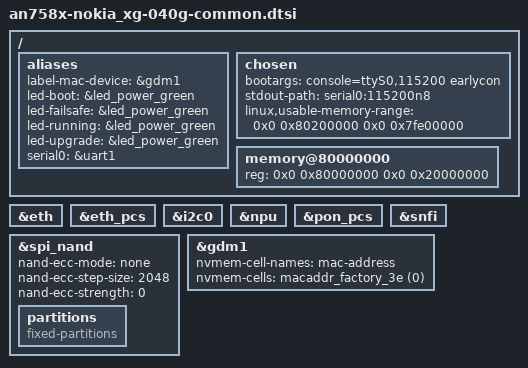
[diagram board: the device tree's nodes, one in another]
// SPDX-License-Identifier: GPL-2.0-only OR MIT

/ {
	aliases {
		label-mac-device = &gdm1;

		led-boot = &led_power_green;
		led-failsafe = &led_power_green;
		led-running = &led_power_green;
		led-upgrade = &led_power_green;

		serial0 = &uart1;
	};

	chosen {
		bootargs = "console=ttyS0,115200 earlycon";
		stdout-path = "serial0:115200n8";
		/*
		 * 这条只是上限裁剪：内核走 memblock_cap_memory_range()，全是 remove，
		 * 只能往少了裁、不会凭空多出内存。真正声明容量的是下面的 memory 节点。
		 * 固定放到 2G，对 512M/1G/2G 任何一种颗粒都不构成裁剪，同时保住起点
		 * 0x80200000 —— 它比 reserved-memory 的 no-map 更早生效，是上游给 ATF
		 * 那 2MB 的第一道保护。
		 */
		linux,usable-memory-range =
			<0x0 0x80200000 0x0 0x7fe00000>;
	};

	/*
	 * 出厂 512M。换过颗粒的机器由 workflow 的 Patch DRAM Size 改写这里；
	 * 若引导程序会 fixup /memory（标准 U-Boot 的 bootm 行为），这里的值会被
	 * 它按实测容量覆盖，改不改都无所谓。
	 */
	memory@80000000 {
		device_type = "memory";
		reg = <0x0 0x80000000 0x0 0x20000000>;
	};
};

&eth {
	status = "okay";
};

&eth_pcs {
	status = "okay";
};

&i2c0 {
	status = "okay";
};

&npu {
	status = "okay";
};

&pon_pcs {
	status = "okay";
};

&snfi {
	status = "okay";
};

&spi_nand {
	/*
	 *  ECC must be aligned with bootloader to prevent read errors.
	 *  Stock fw also uses NAND_ECC_NONE.
	 */
	nand-ecc-mode = "none";
	nand-ecc-step-size = <2048>;
	nand-ecc-strength = <0>;

	partitions: partitions {
		compatible = "fixed-partitions";
		#address-cells = <1>;
		#size-cells = <1>;
	};
};

&gdm1 {
	status = "okay";

	nvmem-cell-names = "mac-address";
	nvmem-cells = <&macaddr_factory_3e (0)>;
};
